AUTOSAR XML (schema 00050)
package /Pkg_ErrorMgrAgg_1_0_A/ComponentTypes
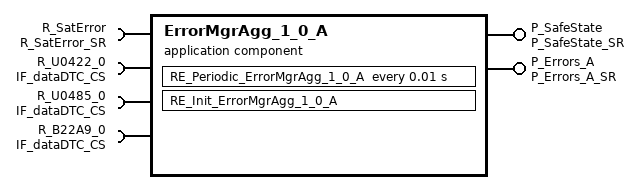
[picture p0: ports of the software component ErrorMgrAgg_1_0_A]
  application sw component type ErrorMgrAgg_1_0_A
    provide port P_SafeState: nonqueued-sender-com-spec{data-element=SafeStateOp, init-value=constant-reference=init_SafeStateOp}, provided-interface=P_SafeState_SR
    provide port P_Errors_A: nonqueued-sender-com-spec=data-element=Errors_A, provided-interface=P_Errors_A_SR
    4 x require port:
      R_SatError: required-interface=R_SatError_SR
        required-com-specs:
          data-element=Data_ErrorMgr_ErrorCommPack_1_0_A, init-value=constant-reference=init_Data_ErrorMgr_ErrorCommPack_1_0_A
          data-element=Data_ErrorMgr_ErrorCommPack_2_0_A, init-value=constant-reference=init_Data_ErrorMgr_ErrorCommPack_2_0_A
          data-element=Data_ErrorMgr_ErrorCommPack_2_1_A, init-value=constant-reference=init_Data_ErrorMgr_ErrorCommPack_2_1_A
          data-element=Data_ErrorMgr_ErrorCommPack_QNX_A, init-value=constant-reference=init_Data_ErrorMgr_ErrorCommPack_QNX_A
      R_U0422_0: client-com-spec=DTCInfo_v, required-interface=IF_dataDTC_CS
      R_U0485_0: client-com-spec=DTCInfo_v, required-interface=IF_dataDTC_CS
      R_B22A9_0: client-com-spec=DTCInfo_v, required-interface=IF_dataDTC_CS
    behavior ErrorMgrAgg_1_0_A_InternalBehavior: handle-termination-and-restart=NO-SUPPORT
      timing event TMT_RE_Periodic_ErrorMgrAgg_1_0_A: start-on-event=RE_Periodic_ErrorMgrAgg_1_0_A, period=0.01
      init event InitEvent: start-on-event=RE_Init_ErrorMgrAgg_1_0_A
      port-api-options:
        enable-take-address=false, error-handling=NO-TRANSFORMER-ERROR-HANDLING, indirect-api=false, port=P_Errors_A
        enable-take-address=false, error-handling=NO-TRANSFORMER-ERROR-HANDLING, indirect-api=false, port=P_SafeState
        enable-take-address=false, error-handling=NO-TRANSFORMER-ERROR-HANDLING, indirect-api=false, port=R_SatError
        enable-take-address=false, error-handling=NO-TRANSFORMER-ERROR-HANDLING, indirect-api=false, port=R_U0422_0
        enable-take-address=false, error-handling=NO-TRANSFORMER-ERROR-HANDLING, indirect-api=false, port=R_U0485_0
        enable-take-address=false, error-handling=NO-TRANSFORMER-ERROR-HANDLING, indirect-api=false, port=R_B22A9_0
      runnable RE_Periodic_ErrorMgrAgg_1_0_A  # Periodic Runnable of Satellite
        data-receive-point-by-arguments:
          4 x access:
            REC_R_SatError_Data_ErrorMgr_ErrorCommPack_1_0_A: accessed-variable=R_SatError.Data_ErrorMgr_ErrorCommPack_1_0_A
            REC_R_SatError_Data_ErrorMgr_ErrorCommPack_2_0_A: accessed-variable=R_SatError.Data_ErrorMgr_ErrorCommPack_2_0_A
            REC_R_SatError_Data_ErrorMgr_ErrorCommPack_2_1_A: accessed-variable=R_SatError.Data_ErrorMgr_ErrorCommPack_2_1_A
            REC_R_SatError_Data_ErrorMgr_ErrorCommPack_QNX_A: accessed-variable=R_SatError.Data_ErrorMgr_ErrorCommPack_QNX_A
        data-send-points:
          access SEND_P_SafeState_SafeStateOp: accessed-variable=P_SafeState.SafeStateOp
          access SEND_P_Errors_A_Errors_A: accessed-variable=P_Errors_A.Errors_A
        sync call SC_R_U0422_0_DTCInfo_v: operation=R_U0422_0.DTCInfo_v, timeout=0
        sync call SC_R_U0485_0_DTCInfo_v: operation=R_U0485_0.DTCInfo_v, timeout=0
        sync call SC_R_B22A9_0_DTCInfo_v: operation=R_B22A9_0.DTCInfo_v, timeout=0
      runnable RE_Init_ErrorMgrAgg_1_0_A  # Init Runnable
  swc implementation ErrorMgrAgg_1_0_A_Implementation: programming-language=C, vendor-id=0, behavior=ErrorMgrAgg_1_0_A_InternalBehavior
    code-descriptors:
      code Default: artifact-descriptors=autosar-engineering-object=category=SWSRC
